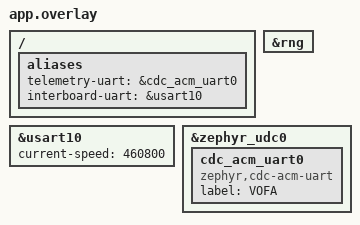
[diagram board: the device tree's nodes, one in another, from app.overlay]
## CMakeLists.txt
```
cmake_minimum_required(VERSION 3.20.0)
find_package(Zephyr REQUIRED HINTS $ENV{ZEPHYR_BASE})
project(gimbal_shared_can LANGUAGES C CXX)
target_sources(app PRIVATE src/main.cpp)
```

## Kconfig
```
mainmenu "Shared CAN mechanical bench"
config SHOOTER_INTERBOARD_BIG_YAW
    bool "Control chassis big Yaw over UART using the RC wheel, without IMU"
    depends on SKYWALKER_INTERBOARD_ENDPOINT && SKYWALKER_UART_TRANSPORT
    default n
    help
        Keep local gimbal/shooter controls and use the existing RC snapshot to
        send manual big-Yaw velocity. Pair with big_yaw_interboard chassis.conf.
        A lost peer revokes only the big-Yaw release gate.

config SHOOTER_UNLOADED_FEED
    bool "Permit unloaded dial indexing"
    default y
    help
        Empty mechanism only. Loaded shooting requires live heat and permission
        sources; these must be wired before disabling this bench bypass.
config SHOOTER_MOUSE_AIM_TELEMETRY
    bool "Use the 19-channel mouse/gimbal tuning telemetry layout"
    depends on SKYWALKER_LIB_VOFA
    default n
    help
        Replace shooter channels with raw mouse input, input age, cycle time,
        joint targets/feedback, effort, validity and saturation flags.
rsource "../common/sample_control.Kconfig"
source "Kconfig.zephyr"
```

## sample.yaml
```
sample:
  name: Shared CAN gimbal and unloaded shooter
common:
  tags: [skywalker, hardware, motor]
  platform_allow: [dm_mc02/stm32h723xx]
  build_only: true
tests:
  sample.skywalker.robotics.gimbal_shared_can: {}
  sample.skywalker.robotics.gimbal_shared_can.diagnostic:
    extra_args: EXTRA_CONF_FILE=diagnostic.conf
```

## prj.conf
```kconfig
CONFIG_CPP=y
CONFIG_STD_CPP20=y
CONFIG_REQUIRES_FULL_LIBCPP=y
CONFIG_MAIN_STACK_SIZE=8192
CONFIG_HEAP_MEM_POOL_SIZE=0
CONFIG_LOG=y
CONFIG_SERIAL=y
CONFIG_UART_ASYNC_API=y
CONFIG_NOCACHE_MEMORY=y
CONFIG_CAN=y
CONFIG_SKYWALKER_DRIVER_MOTOR=y
CONFIG_SKYWALKER_MOTOR_DJI=y
CONFIG_SKYWALKER_MOTOR_DM=y
CONFIG_SKYWALKER_LIB_MOTOR_CONTROL=y
CONFIG_SKYWALKER_LIB_COMMUNICATION=y
CONFIG_SKYWALKER_UART_TRANSPORT=y
CONFIG_SKYWALKER_REMOTE_DR16=y
CONFIG_SKYWALKER_REMOTE_RECEIVER=y
CONFIG_SKYWALKER_REFEREE=n
CONFIG_SKYWALKER_INTERBOARD=n
CONFIG_SKYWALKER_LIB_ROBOTICS=y
CONFIG_SKYWALKER_COMMAND_SERVICE=y
CONFIG_SKYWALKER_ROBOTICS_GIMBAL=y
CONFIG_SKYWALKER_ROBOTICS_SHOOTER=y
CONFIG_SKYWALKER_ROBOTICS_SWERVE=n

# USB CDC telemetry; console remains on the board UART.
CONFIG_SKYWALKER_LIB_VOFA=y
CONFIG_USB_DEVICE_STACK_NEXT=y
CONFIG_CDC_ACM_SERIAL_INITIALIZE_AT_BOOT=y
CONFIG_CDC_ACM_SERIAL_PRODUCT_STRING="SkyWalker Telemetry"
CONFIG_USBD_CDC_ACM_LOG_LEVEL_WRN=y
```

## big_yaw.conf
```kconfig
# Local gimbal/shooter plus manual big Yaw on the peer; no inertial control.
CONFIG_SHOOTER_INTERBOARD_BIG_YAW=y
CONFIG_SKYWALKER_INTERBOARD=y
CONFIG_SKYWALKER_INTERBOARD_ENDPOINT=y
CONFIG_ENTROPY_GENERATOR=y
CONFIG_FPU=y
CONFIG_FPU_SHARING=y
CONFIG_SKYWALKER_IMU=n
CONFIG_SKYWALKER_ROBOTICS_INERTIAL_GIMBAL=n
```

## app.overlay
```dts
/* Shared CAN1 motors and independent Pitch CAN2 use the board wiring. */
/ {
    aliases {
        telemetry-uart = &cdc_acm_uart0;
        interboard-uart = &usart10;
    };
};

/* Optional big_yaw.conf owns USART1; USB CDC continues to carry VOFA. */
&usart10 {
    current-speed = <460800>;
};

&rng {
    status = "okay";
};

&zephyr_udc0 {
    cdc_acm_uart0: cdc_acm_uart0 {
        compatible = "zephyr,cdc-acm-uart";
        label = "VOFA";
    };
};
```

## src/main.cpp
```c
#include "../../common/shooter_bench.hpp"
#if defined(CONFIG_SHOOTER_INTERBOARD_BIG_YAW)
K_THREAD_DEFINE(shared_can_big_yaw_link, 4096, skywalker::samples::manual_big_yaw::communicationTask, nullptr, nullptr,
                nullptr, 6, K_FP_REGS, 0);
#endif
int main() {
#if defined(CONFIG_SHOOTER_INTERBOARD_BIG_YAW)
    printk("bigYaw: UART1 460800; RC wheel +/-0.1 rad/s in RC and keyboard/mouse modes; no IMU\n");
#endif
    return skywalker::samples::shooter::run(true, IS_ENABLED(CONFIG_SHOOTER_UNLOADED_FEED));
}
```
